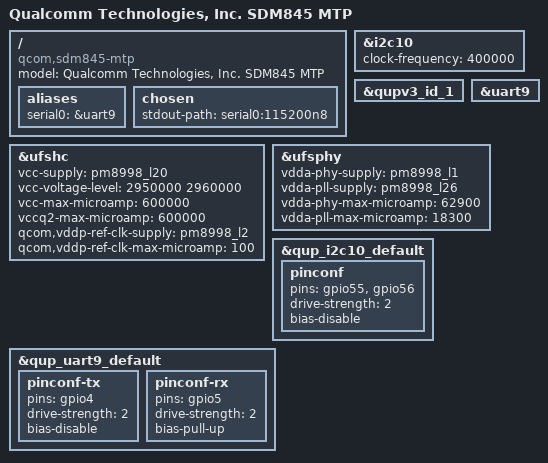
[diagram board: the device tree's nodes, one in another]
// SPDX-License-Identifier: GPL-2.0
/*
 * SDM845 MTP board device tree source
 *
 * Copyright (c) 2018, The Linux Foundation. All rights reserved.
 */

/dts-v1/;

#include "sdm845.dtsi"

/ {
	model = "Qualcomm Technologies, Inc. SDM845 MTP";
	compatible = "qcom,sdm845-mtp";

	aliases {
		serial0 = &uart9;
	};

	chosen {
		stdout-path = "serial0:115200n8";
	};
};

&i2c10 {
	status = "okay";
	clock-frequency = <400000>;
};

&qupv3_id_1 {
	status = "okay";
};

&uart9 {
	status = "okay";
};

&ufshc {
	status = "okay";

	vcc-supply = <&pm8998_l20>;
	vcc-voltage-level = <2950000 2960000>;
	vcc-max-microamp = <600000>;
	vccq2-max-microamp = <600000>;

	qcom,vddp-ref-clk-supply = <&pm8998_l2>;
	qcom,vddp-ref-clk-max-microamp = <100>;
};

&ufsphy {
	status = "okay";

	vdda-phy-supply = <&pm8998_l1>; /* 0.88v */
	vdda-pll-supply = <&pm8998_l26>; /* 1.2v */
	vdda-phy-max-microamp = <62900>;
	vdda-pll-max-microamp = <18300>;
};

/* PINCTRL - additions to nodes defined in sdm845.dtsi */

&qup_i2c10_default {
	pinconf {
		pins = "gpio55", "gpio56";
		drive-strength = <2>;
		bias-disable;
	};
};

&qup_uart9_default {
	pinconf-tx {
		pins = "gpio4";
		drive-strength = <2>;
		bias-disable;
	};

	pinconf-rx {
		pins = "gpio5";
		drive-strength = <2>;
		bias-pull-up;
	};
};
